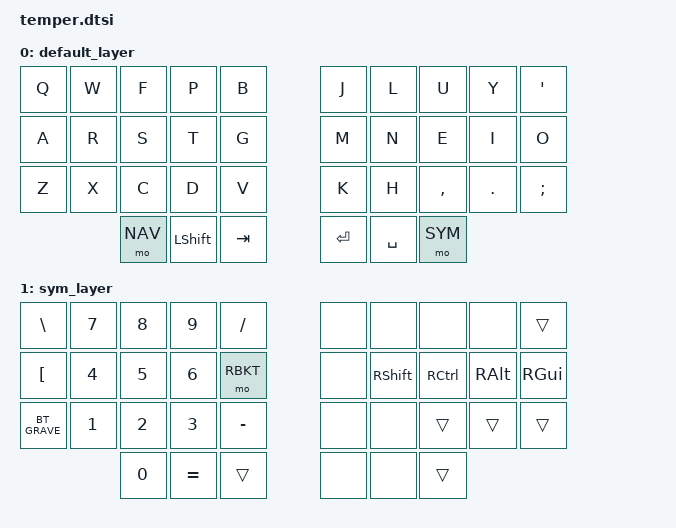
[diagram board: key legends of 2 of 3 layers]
/*
 * Copyright (c) 2020 The ZMK Contributors
 *
 * SPDX-License-Identifier: MIT
 */

#include <behaviors.dtsi>
#include <dt-bindings/zmk/keys.h>
#include <dt-bindings/zmk/bt.h>

#define DEFAULT 0
#define SYMBOLS 1
#define NAV     2
// #define FPS     3

/ {
        keymap {
                compatible = "zmk,keymap";

                default_layer {
// -----------------------------------------------------------------------------------------
// |  Q  |  W  |  F  |  P  |  B   |   |  J  |  L   |  U  |  Y  |  '  |
// |  A  |  R  |  S  |  T  |  G   |   |  M  |  N   |  E  |  I  |  O  |
// |  Z  |  X  |  C  |  D  |  V   |   |  K  |  H   |  ,  |  .  |  ;  |
//             | NAV | SHF | TAB  |   | ENT | SPC  | SYM |
                        bindings = <
   &kp Q &kp W &kp F &kp P &kp B   &kp J &kp L  &kp U     &kp Y   &kp APOS
   &kp A &kp R &kp S &kp T &kp G   &kp M &kp N  &kp E     &kp I   &kp O
   &kp Z &kp X &kp C &kp D &kp V   &kp K &kp H  &kp COMMA &kp DOT &kp SEMI
        &mo NAV &kp LSHFT &kp TAB  &kp ENTER &kp SPACE &mo SYM
                        >;
                };
                sym_layer {
// -----------------------------------------------------------------------------------------
// |  \  |  7  |  8  |  9   |  /  |   |     |      |      |      |      |
// |  [  |  4  |  5  |  6   |  ]  |   |     | SHFT | CNTL | RALT | RGUI |
// |  `  |  1  |  2  |  3   |  -  |   |     |      |      |      |      |
//             |     |      |     |   |     |      |      |
                        bindings = <
   &kp BSLH   &kp N7   &kp N8   &kp N9   &kp FSLH       &none  &none      &none      &none     &trans
   &kp LBKT   &kp N4   &kp N5   &kp N6   &mo RBKT       &none  &kp RSHFT  &kp RCTRL  &kp RALT  &kp RGUI
   &bt GRAVE  &kp N1   &kp N2   &kp N3   &kp MINUS      &none  &none      &trans   &trans   &trans
                       &kp N0   &kp EQUAL    &trans     &none  &none      &trans
                        >;
                };

                nav_layer {
// -----------------------------------------------------------------------------------------
// | ESC  |      |       |       |     |   |     | HOME |  UP  |  END  |     |
// | LGUI | LALT | LCTRL | LSHFT |     |   |BKSP | LEFT | DOWN | RIGHT | DEL |
// |      | CUT  |  CPY  | PSTE  |     |   |     |      |      |       |     |
//               | &trans|       |     |   |     |      |      |
                        bindings = <
   &kp ESC   &none     &none   &none   &none      &none    &kp HOME   &kp UP  &kp END  &none
   &kp LGUI  &kp LALT  &LCTRL  &LSHFT  &none      &kp BKSP &kp LEFT   &kp DOWN  &kp RIGHT &kp DEL
   &none     &kp K_CUT &kp K_COPY  &kp K_PASTE    &none    &none      &none   &none   &none
                       &trans  &none   &none      &trans   &trans     &none
                        >;
                };
        };
};
